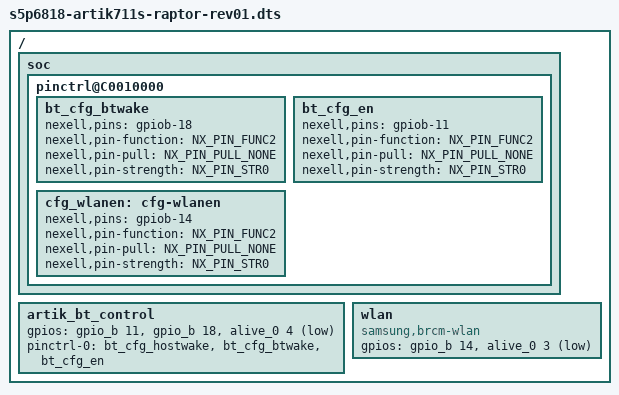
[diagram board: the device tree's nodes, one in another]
/*
 * Copyright (C) 2018 Samsung Electronics
 * Author: Chanho Park <chanho61.park@samsung.com>
 *
 * This program is free software; you can redistribute it and/or
 * modify it under the terms of the GNU General Public License
 * as published by the Free Software Foundation; either version 2
 * of the License, or (at your option) any later version.
 *
 * This program is distributed in the hope that it will be useful,
 * but WITHOUT ANY WARRANTY; without even the implied warranty of
 * MERCHANTABILITY or FITNESS FOR A PARTICULAR PURPOSE.  See the
 * GNU General Public License for more details.
 *
 * You should have received a copy of the GNU General Public License
 * along with this program.  If not, see <http://www.gnu.org/licenses/>.
 */

/dts-v1/;
#include "s5p6818-artik711s-raptor-common.dtsi"
/ {
	soc {
		pinctrl@C0010000 {
			bt_cfg_btwake:bt_cfg_btwake {
				nexell,pins = "gpiob-18";
				nexell,pin-function = <NX_PIN_FUNC2>;
				nexell,pin-pull = <NX_PIN_PULL_NONE>;
				nexell,pin-strength = <NX_PIN_STR0>;
			};

			bt_cfg_en:bt_cfg_en {
				nexell,pins = "gpiob-11";
				nexell,pin-function = <NX_PIN_FUNC2>;
				nexell,pin-pull = <NX_PIN_PULL_NONE>;
				nexell,pin-strength = <NX_PIN_STR0>;
			};

			cfg_wlanen: cfg-wlanen {
				nexell,pins = "gpiob-14";
				nexell,pin-function = <NX_PIN_FUNC2>;
				nexell,pin-pull = <NX_PIN_PULL_NONE>;
				nexell,pin-strength = <NX_PIN_STR0>;
			};
		};
	};	/* soc */

	artik_bt_control {
		gpios = <&gpio_b 11 0	/* GPIOB11=BT_EN, output */
			&gpio_b 18 0	/* GPIOB18=BT_WAKE, output */
			&alive_0 4 1	/* AliveGPIO4=BT_HOST_WAKE, input */
			>;
		pinctrl-names = "default";
		pinctrl-0 = <&bt_cfg_hostwake &bt_cfg_btwake &bt_cfg_en>;
		status = "okay";
	};

	wlan {
		compatible = "samsung,brcm-wlan";
		gpios = <&gpio_b 14 0	/* WLAN_EN */
			&alive_0 3 1>;	/* WLAN_HOST_WAKE */
		status = "okay";
	};
};
